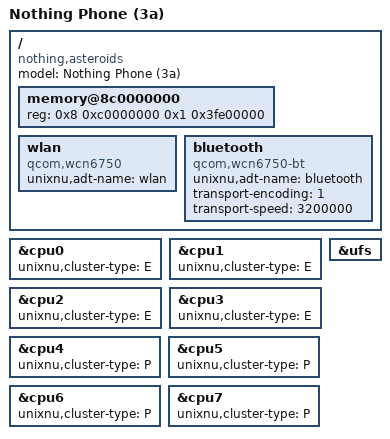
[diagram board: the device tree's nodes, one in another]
// SPDX-License-Identifier: BSD-3-Clause
// Nothing Phone (3a): the board's memory and CPU selection on the shared SM7635 resources.
/dts-v1/;
/include/ "sm7635.dtsi"

/ {
    model = "Nothing Phone (3a)";
    compatible = "nothing,asteroids", "qcom,volcano";

    // The DRAM the XNU window lives in: the high bank from 0x8C0000000 (uke's layout, T19), whole since T64 (no GPU pool at its top).
    // DarwinBoot places owned_memory_size (board.toml [payload.adt]) there; board.toml [payload] dram_size must equal the size.
    memory@8c0000000 {
        device_type = "memory";
        reg = <0x8 0xc0000000 0x1 0x3fe00000>;   // 8 GB unit (12 GB: 0x2 0x3fe00000)
    };

    // launchd starts wifid (the Wi-Fi status, Settings' Wi-Fi state, the network time trigger) only when the device tree has a
    // node named "wlan" (com.apple.wifid.plist _LimitLoadToDeviceTree), as sheng's port exports it. The radio itself is driven by
    // AsteroidsWifi and WifiNet (en0, Apple80211); nothing matches this node.
    wlan {
        compatible = "qcom,wcn6750";
        unixnu,adt-name = "wlan";
        status = "okay";
    };

    // The WCN6750's Bluetooth (package/BluetoothProbe.cpp, bluetooth=1), as sheng's port exports its WCN7850: an H4 UART
    // (transport-encoding 1) at 3.2 Mbaud. The probe checks both, fills local-mac-address and publishes a matching IOService before
    // userland; bluetoothd reads the transport from here.
    bluetooth {
        device_type = "bluetooth";
        compatible = "qcom,wcn6750-bt";
        unixnu,adt-name = "bluetooth";
        transport-encoding = <1>;
        transport-speed = <3200000>;
        status = "okay";
    };
};

// The scheduler runs the A520 cores as an E cluster and the A720 cores as a P cluster (UniXNU's AMP patch, zzyf).
&cpu0 { unixnu,cluster-type = "E"; };
&cpu1 { unixnu,cluster-type = "E"; };
&cpu2 { unixnu,cluster-type = "E"; };
&cpu3 { unixnu,cluster-type = "E"; };
&cpu4 { unixnu,cluster-type = "P"; };
&cpu5 { unixnu,cluster-type = "P"; };
&cpu6 { unixnu,cluster-type = "P"; };
&cpu7 { unixnu,cluster-type = "P"; };
&ufs { status = "okay"; };
